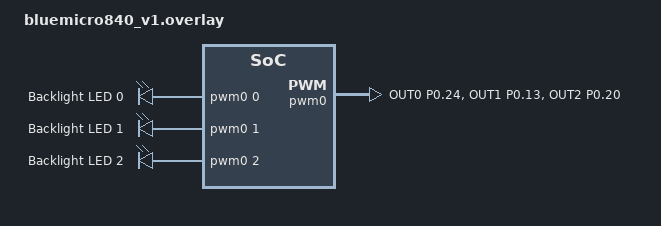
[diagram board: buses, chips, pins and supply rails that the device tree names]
/*
 * Copyright (c) 2022 The ZMK Contributors
 *
 * SPDX-License-Identifier: MIT
 */


&pinctrl {
	pwm0_default: pwm0_default {
		group0 {
			psels = <NRF_PSEL(PWM_OUT0, 0, 24)>, <NRF_PSEL(PWM_OUT1, 0, 13)>, <NRF_PSEL(PWM_OUT2, 0, 20)>;
		};
	};

	pwm0_sleep: pwm0_sleep {
		group0 {
			psels = <NRF_PSEL(PWM_OUT0, 0, 24)>, <NRF_PSEL(PWM_OUT1, 0, 13)>, <NRF_PSEL(PWM_OUT2, 0, 20)>;
			low-power-enable;
		};
	};
};

&pwm0 {
	status = "okay";
	pinctrl-0 = <&pwm0_default>;
	pinctrl-1 = <&pwm0_sleep>;
	pinctrl-names = "default", "sleep";
};

/ {
    backlight: pwmleds {
        compatible = "pwm-leds";
        label = "Backlight LEDs";
        pwm_led_0 {
            pwms = <&pwm0 0 PWM_MSEC(20) PWM_POLARITY_NORMAL>;
            label = "Backlight LED 0";
        };
        pwm_led_1 {
            pwms = <&pwm0 1 PWM_MSEC(20) PWM_POLARITY_NORMAL>;
            label = "Backlight LED 1";
        };
        pwm_led_2 {
            pwms = <&pwm0 2 PWM_MSEC(20) PWM_POLARITY_NORMAL>;
            label = "Backlight LED 2";
        };
    };

    chosen {
        zmk,backlight = &backlight;
    };
};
